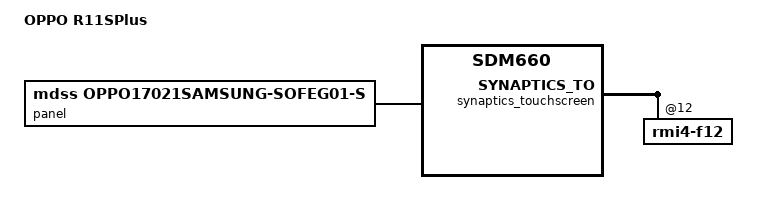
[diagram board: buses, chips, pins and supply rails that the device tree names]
// SPDX-License-Identifier: GPL-2.0-only
/*
* Copyright (c) 2025, XiKoTaSu <3329989998@qq.com>
*/

/dts-v1/;

#include "sdm660-oppo-common.dtsi"

/ {
	model = "OPPO R11SPlus";
	compatible = "oppo,r11splus", "qcom,sdm660";
	chassis-type = "handset";

	aliases {
		serial0 = &blsp1_uart2;
        serial1 = &blsp2_uart1; /* Bluetooth UART */
	};

	chosen {
		#address-cells = <2>;
		#size-cells = <2>;
		ranges;

		/* stdout-path = "serial0:115200n8"; */

		framebuffer0: framebuffer@9d400000 {
			compatible = "simple-framebuffer";
			reg = <0 0x9d400000 0 0x23000000>;
			width = <1080>;
			height = <2160>;
			stride = <(1080 * 4)>;
			format = "a8r8g8b8";
		};
	};
};

&panel {
	compatible = "mdss,oppo17021samsung-sofeg01-s";
};

&synaptics_touchscreen {
	rmi4-f12@12 {
		reg = <0x12>;
		syna,sensor-type = <1>;
		syna,rezero-wait-ms = <200>;
		syna,clip-x-low = <0>;
		syna,clip-x-high = <1080>;
	    syna,clip-y-low = <0>;
		syna,clip-y-high = <2160>;
	};
};
